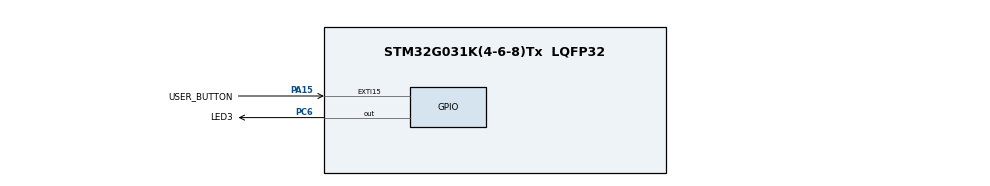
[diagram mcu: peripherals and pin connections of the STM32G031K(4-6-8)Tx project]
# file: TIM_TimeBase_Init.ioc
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Mcu.Family=STM32G0
Mcu.Name=STM32G031K(4-6-8)Tx
Mcu.Package=LQFP32
NVIC.EXTI4_15_IRQn=true\:0\:0\:false\:false\:true\:true\:true\:true
NVIC.TIM1_BRK_UP_TRG_COM_IRQn=true\:0\:0\:false\:false\:true\:true\:true\:true
PA15.GPIO_Label=USER_BUTTON
PA15.GPIO_ModeDefaultEXTI=GPIO_MODE_IT_FALLING
PA15.GPIO_PuPd=GPIO_PULLUP
PA15.Signal=GPXTI15
PC6.GPIO_Label=LED3
PC6.Signal=GPIO_Output
ProjectManager.HeapSize=0x200
ProjectManager.StackSize=0x400
ProjectManager.TargetToolchain=EWARM V8.50
RCC.ADCFreq_Value=64000000
RCC.AHBFreq_Value=64000000
RCC.CortexFreq_Value=64000000
RCC.EXTERNAL_CLOCK_VALUE=48000000
RCC.HCLKFreq_Value=64000000
RCC.HSE_VALUE=8000000
RCC.HSI_VALUE=16000000
RCC.LSE_VALUE=32768
RCC.SYSCLKFreq_VALUE=64000000
RCC.SYSCLKSource=RCC_SYSCLKSOURCE_PLLCLK
RCC.VCOOutputFreq_Value=128000000
TIM1.AutoReloadPreload=TIM_AUTORELOAD_PRELOAD_DISABLE
TIM1.ClockDivision=TIM_CLOCKDIVISION_DIV1
TIM1.CounterMode=TIM_COUNTERMODE_UP
TIM1.Period=tim_period
TIM1.Prescaler=tim_prescaler
TIM1.RepetitionCounter=0
TIM1.TIM_MasterOutputTrigger=TIM_TRGO_RESET
TIM1.TIM_MasterOutputTrigger2=TIM_TRGO2_RESET
TIM1.TIM_MasterSlaveMode=TIM_MASTERSLAVEMODE_DISABLE
VP_TIM1_VS_ClockSourceINT.Mode=Internal
board=custom

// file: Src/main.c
/* USER CODE BEGIN Header */
/**
  ******************************************************************************
  * @file    Examples_LL/TIM/TIM_TimeBase_Init/Src/main.c
  * @author  MCD Application Team
  * @brief   This example describes how to use a timer instance to generate a
  *          time base using the STM32G0xx TIM LL API.
  *          Peripheral initialization done using LL unitary services functions.
  ******************************************************************************
  * @attention
  *
  * Copyright (c) 2019-2021 STMicroelectronics.
  * All rights reserved.
  *
  * This software is licensed under terms that can be found in the LICENSE file
  * in the root directory of this software component.
  * If no LICENSE file comes with this software, it is provided AS-IS.
  *
  ******************************************************************************
  */
/* USER CODE END Header */
#include "main.h"

/* USER CODE BEGIN PD */
/* Number of time base frequencies */
#define TIM_BASE_FREQ_NB 10
/* USER CODE END PD */

/* USER CODE BEGIN PV */
static uint32_t tim_prescaler = 0;
static uint32_t tim_period = 0;
static uint32_t TimOutClock = 1;

/* Actual autoreload value multiplication factor */
static uint8_t AutoreloadMult = 1;

/* Debounce delay */
static uint32_t Wait200ms = 0;
/* USER CODE END PV */

void SystemClock_Config(void);
static void MX_GPIO_Init(void);
static void MX_TIM1_Init(void);

int main(void)
{

  /* MCU Configuration--------------------------------------------------------*/

  /* Reset of all peripherals, Initializes the Flash interface and the Systick. */
  LL_APB2_GRP1_EnableClock(LL_APB2_GRP1_PERIPH_SYSCFG);
  LL_APB1_GRP1_EnableClock(LL_APB1_GRP1_PERIPH_PWR);

  /* Configure the system clock */
  SystemClock_Config();

  /* USER CODE BEGIN SysInit */
  /* Set the pre-scaler value to have TIM1 counter clock equal to 10 kHz      */
  /*
   In this example TIM1 input clock TIM1CLK is set to APB2 clock (PCLK2),
   since APB2 pre-scaler is equal to 1.
      TIM1CLK = PCLK2
      PCLK1 = HCLK
      => TIM1CLK = SystemCoreClock (56 MHz)
  */
  tim_prescaler = __LL_TIM_CALC_PSC(SystemCoreClock, 10000);

  /* TIM1CLK = SystemCoreClock / (APB prescaler & multiplier)              */
  TimOutClock = SystemCoreClock/1;
  tim_period = __LL_TIM_CALC_ARR(TimOutClock, tim_prescaler, 10);
  /* USER CODE END SysInit */

  /* Initialize all configured peripherals */
  MX_GPIO_Init();
  MX_TIM1_Init();
  /* USER CODE BEGIN 2 */
  /* Clear the update flag */
  LL_TIM_ClearFlag_UPDATE(TIM1);

  /* Enable the update interrupt */
  LL_TIM_EnableIT_UPDATE(TIM1);

  /* Enable counter */
  LL_TIM_EnableCounter(TIM1);
  /* USER CODE END 2 */

  /* Infinite loop */
  /* USER CODE BEGIN WHILE */
  /* Configure the Cortex-M SysTick source to have 1ms time base */
  LL_Init1msTick(SystemCoreClock);

  while (1)
  {
    if (Wait200ms == 1)
    {
      /* Wait 200 ms */
      LL_mDelay(200);

      /* Clear debounce flag */
      Wait200ms = 0;
    }
    /* USER CODE END WHILE */

  }
}

void SystemClock_Config(void)
{
  LL_FLASH_SetLatency(LL_FLASH_LATENCY_2);
  while(LL_FLASH_GetLatency() != LL_FLASH_LATENCY_2)
  {
  }

  /* HSI configuration and activation */
  LL_RCC_HSI_Enable();
  while(LL_RCC_HSI_IsReady() != 1)
  {
  }

  /* Main PLL configuration and activation */
  LL_RCC_PLL_ConfigDomain_SYS(LL_RCC_PLLSOURCE_HSI, LL_RCC_PLLM_DIV_1, 8, LL_RCC_PLLR_DIV_2);
  LL_RCC_PLL_Enable();
  LL_RCC_PLL_EnableDomain_SYS();
  while(LL_RCC_PLL_IsReady() != 1)
  {
  }

  /* Set AHB prescaler*/
  LL_RCC_SetAHBPrescaler(LL_RCC_SYSCLK_DIV_1);

  /* Sysclk activation on the main PLL */
  LL_RCC_SetSysClkSource(LL_RCC_SYS_CLKSOURCE_PLL);
  while(LL_RCC_GetSysClkSource() != LL_RCC_SYS_CLKSOURCE_STATUS_PLL)
  {
  }

  /* Set APB1 prescaler*/
  LL_RCC_SetAPB1Prescaler(LL_RCC_APB1_DIV_1);

  LL_Init1msTick(64000000);

  /* Update CMSIS variable (which can be updated also through SystemCoreClockUpdate function) */
  LL_SetSystemCoreClock(64000000);
}

static void MX_TIM1_Init(void)
{

  LL_TIM_InitTypeDef TIM_InitStruct = {0};

  LL_RCC_SetTIMClockSource(LL_RCC_TIM1_CLKSOURCE_PCLK1);

  /* Peripheral clock enable */
  LL_APB2_GRP1_EnableClock(LL_APB2_GRP1_PERIPH_TIM1);

  /* TIM1 interrupt Init */
  NVIC_SetPriority(TIM1_BRK_UP_TRG_COM_IRQn, 0);
  NVIC_EnableIRQ(TIM1_BRK_UP_TRG_COM_IRQn);

  TIM_InitStruct.Prescaler = tim_prescaler;
  TIM_InitStruct.CounterMode = LL_TIM_COUNTERMODE_UP;
  TIM_InitStruct.Autoreload = tim_period;
  TIM_InitStruct.ClockDivision = LL_TIM_CLOCKDIVISION_DIV1;
  TIM_InitStruct.RepetitionCounter = 0;
  LL_TIM_Init(TIM1, &TIM_InitStruct);
  LL_TIM_DisableARRPreload(TIM1);
  LL_TIM_SetClockSource(TIM1, LL_TIM_CLOCKSOURCE_INTERNAL);
  LL_TIM_SetTriggerOutput(TIM1, LL_TIM_TRGO_RESET);
  LL_TIM_SetTriggerOutput2(TIM1, LL_TIM_TRGO2_RESET);
  LL_TIM_DisableMasterSlaveMode(TIM1);

}

static void MX_GPIO_Init(void)
{
  LL_EXTI_InitTypeDef EXTI_InitStruct = {0};
  LL_GPIO_InitTypeDef GPIO_InitStruct = {0};

  /* GPIO Ports Clock Enable */
  LL_IOP_GRP1_EnableClock(LL_IOP_GRP1_PERIPH_GPIOC);
  LL_IOP_GRP1_EnableClock(LL_IOP_GRP1_PERIPH_GPIOA);

  /**/
  LL_GPIO_ResetOutputPin(LED3_GPIO_Port, LED3_Pin);

  /**/
  GPIO_InitStruct.Pin = LED3_Pin;
  GPIO_InitStruct.Mode = LL_GPIO_MODE_OUTPUT;
  GPIO_InitStruct.Speed = LL_GPIO_SPEED_FREQ_LOW;
  GPIO_InitStruct.OutputType = LL_GPIO_OUTPUT_PUSHPULL;
  GPIO_InitStruct.Pull = LL_GPIO_PULL_NO;
  LL_GPIO_Init(LED3_GPIO_Port, &GPIO_InitStruct);

  /**/
  LL_EXTI_SetEXTISource(LL_EXTI_CONFIG_PORTA, LL_EXTI_CONFIG_LINE15);

  /**/
  EXTI_InitStruct.Line_0_31 = LL_EXTI_LINE_15;
  EXTI_InitStruct.LineCommand = ENABLE;
  EXTI_InitStruct.Mode = LL_EXTI_MODE_IT;
  EXTI_InitStruct.Trigger = LL_EXTI_TRIGGER_FALLING;
  LL_EXTI_Init(&EXTI_InitStruct);

  /**/
  LL_GPIO_SetPinPull(USER_BUTTON_GPIO_Port, USER_BUTTON_Pin, LL_GPIO_PULL_UP);

  /**/
  LL_GPIO_SetPinMode(USER_BUTTON_GPIO_Port, USER_BUTTON_Pin, LL_GPIO_MODE_INPUT);

  /* EXTI interrupt init*/
  NVIC_SetPriority(EXTI4_15_IRQn, 0);
  NVIC_EnableIRQ(EXTI4_15_IRQn);

}

/* USER CODE BEGIN 4 */

/******************************************************************************/
/*   USER IRQ HANDLER TREATMENT                                               */
/******************************************************************************/
/**
  * @brief  Update the timer update event period
  * @param  None
  * @retval None
  */
void UserButton_Callback(void)
{
  if (Wait200ms == 0)
  {
    /* Set debounce flag */
    Wait200ms = 1;

    /* Change the update event period by modifying the autoreload value.        */
    /* In up-counting update event is generated at each counter overflow (when  */
    /* the counter reaches the auto-reload value).                              */
    /* Update event period is calculated as follows:                            */
    /*   Update_event = TIM1CLK /((PSC + 1)*(ARR + 1)*(RCR + 1))                */
    /*   where TIM1CLK is 64 MHz                                                */
    AutoreloadMult = AutoreloadMult % TIM_BASE_FREQ_NB;
    LL_TIM_SetAutoReload(TIM1, tim_period * (AutoreloadMult +1));

    /* Force update generation */
    LL_TIM_GenerateEvent_UPDATE(TIM1);

    AutoreloadMult++;
  }
}

/**
  * @brief  Timer update interrupt processing
  * @param  None
  * @retval None
  */
void TimerUpdate_Callback(void)
{
  LL_GPIO_TogglePin(LED3_GPIO_Port, LED3_Pin);
}
/* USER CODE END 4 */

void Error_Handler(void)
{
}
